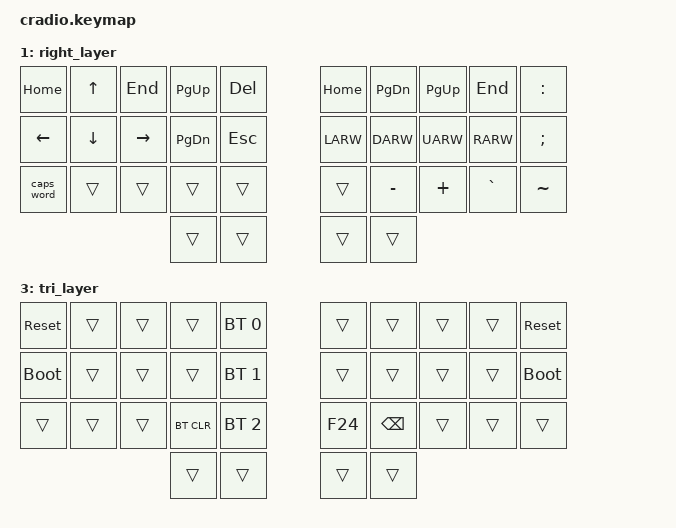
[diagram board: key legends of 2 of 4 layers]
// Copyright (c) 2022 The ZMK Contributors
// SPDX-License-Identifier: MIT

#include <behaviors.dtsi>
#include <dt-bindings/zmk/keys.h>
#include <dt-bindings/zmk/bt.h>

// Home row mods macro
#define HRML(k1,k2,k3,k4) &ht LSHFT k1  &ht LALT k2  &ht LCTRL k3  &ht LGUI k4
#define HRMR(k1,k2,k3,k4) &ht RGUI k1  &ht RCTRL k2  &ht RALT k3  &ht RSHFT k4
#define HYPER(k1) &ht LS(LC(LA(LGUI))) k1
#define HYPER_F(k1) &ht F24 k1
#define MEHL(k1) &ht LS(LC(LA))) k1
#define MEHR(K1) &ht RS(RC(RA))) k1

/ {
    behaviors {
        ht: hold_tap {
            label = "hold_tap";
            compatible = "zmk,behavior-hold-tap";
            #binding-cells = <2>;
            flavor = "tap-preferred";
            tapping-term-ms = <220>;
            quick-tap-ms = <150>;
            global-quick-tap;
            bindings = <&kp>, <&kp>;
        };
    };

    conditional_layers {
        compatible = "zmk,conditional-layers";
        tri_layer {
            if-layers = <1 2>;
            then-layer = <3>;
        };
    };

    keymap {
        compatible = "zmk,keymap";
        default_layer {
            bindings = <
        //╭──────────┬──────────┬──────────┬──────────┬──────────╮   ╭──────────┬──────────┬──────────┬──────────┬──────────╮
        //│  Q       │  W       │  E       │  R       │  T       │   │  Y       │  U       │  I       │  O       │  P       │
            HYPER(Q)    &kp W      &kp E      &kp R      &kp T          &kp Y      &kp U      &kp I      &kp O     HYPER(P)
        //├──────────┼──────────┼──────────┼──────────┼──────────┤   ├──────────┼──────────┼──────────┼──────────┼──────────┤
        //│  A       │  S       │  D       │  F       │  G       │   │  H       │  J       │  K       │  L       │ ' "      │
            HRML(A,        S,         D,         F)     MEHL(G)       MEHR(H)    HRMR(J,        K,         L,        SQT)
        //├──────────┼──────────┼──────────┼──────────┼──────────┤   ├──────────┼──────────┼──────────┼──────────┼──────────┤
        //│  Z       │  X       │  C       │  V       │  B       │   │  N       │  M       │ , <      │ . >      │ / ?      │
            HYPER_F(Z)    &kp X      &kp C      &kp V      &kp B          &kp N      &kp M      &kp COMMA  &kp DOT    HYPER_F(FSLH)
        //╰──────────┴──────────┴──────────┼──────────┼──────────┤   ├──────────┼──────────┼──────────┴──────────┴──────────╯
                                            &lt 2 TAB   &kp SPACE     &kp ENTER  &lt 1 BSPC
        //                                 ╰──────────┴──────────╯   ╰──────────┴──────────╯
            >;
        };

        right_layer {
            bindings = <
        //╭──────────┬──────────┬──────────┬──────────┬──────────╮   ╭──────────┬──────────┬──────────┬──────────┬──────────╮
        //│ HOME     │ UP       │  END     │ PAGE UP  │ DEL      │   │ HOME     │ PAGE DN  │ PAGE UP  │ END      │  :       │
            &kp HOME   &kp UP     &kp END   &kp PG_UP  &kp DEL          &kp HOME   &kp PG_DN  &kp PG_UP  &kp END    &kp COLON
        //├──────────┼──────────┼──────────┼──────────┼──────────┤   ├──────────┼──────────┼──────────┼──────────┼──────────┤
        //│ LEFT     │  DOWN    │ RIHT     │ PAGE DOWN│ ESC      │   │ LEFT     │ DOWN     │ UP       │ RIGHT    │  ;       │
           &kp LEFT   &kp DOWN   &kp RIGHT  &kp PG_DN  &kp ESC         &kp LARW   &kp DARW   &kp UARW   &kp RARW   &kp SEMI
        //├──────────┼──────────┼──────────┼──────────┼──────────┤   ├──────────┼──────────┼──────────┼──────────┼──────────┤
        //│ CAPS     │ PRINT SC │volume up │volume dwn│  Next    │   │ PREV SONG│    -     │     +    │   `      │   ~      │
           &caps_word  &trans   &trans      &trans     &trans         &trans      &kp MINUS  &kp PLUS   &kp GRAVE  &kp TILDE
        //╰──────────┴──────────┴──────────┼──────────┼──────────┤   ├──────────┼──────────┼──────────┴──────────┴──────────╯
                                             &trans      &trans        &trans     &trans
        //                                 ╰──────────┴──────────╯   ╰──────────┴──────────╯
            >;
        };

        left_layer {
            bindings = <
        //╭──────────┬──────────┬──────────┬──────────┬──────────╮   ╭──────────┬──────────┬──────────┬──────────┬──────────╮
        //│    !     │  @       │  #       │  $       │ %        │   │  ^       │  &       │  *       │  (       │  )       │
            &kp EXCL   &kp AT     &kp HASH   &kp DLLR   &kp PRCNT      &kp CARET   &kp AMPS   &kp ASTRK  &kp LPAR  &kp RPAR  
        //├──────────┼──────────┼──────────┼──────────┼──────────┤   ├──────────┼──────────┼──────────┼──────────┼──────────┤
        //│   1      │  2       │  3       │  4       │  5       │   │  6       │  7       │  8       │  9       │  0       │
            HRML(N1,    N2,       N3,        N4)        &kp N5         &kp N6     HRMR(N7,   N8,        N9,         N0)
        //├──────────┼──────────┼──────────┼──────────┼──────────┤   ├──────────┼──────────┼──────────┼──────────┼──────────┤
        //│  esc     │          │  _       │    =     │  del     │   │  [       │   ]      │  <       │  >       │         │
           &kp ESC     &kp BSLH  &kp UNDER &kp EQUAL   &kp DEL       &kp LBKT    &kp RBKT   &kp LT     &kp GT     &kp PIPE  
        //╰──────────┴──────────┴──────────┼──────────┼──────────┤   ├──────────┼──────────┼──────────┴──────────┴──────────╯
                                             &trans     &trans         &trans     &trans
        //                                 ╰──────────┴──────────╯   ╰──────────┴──────────╯
            >;
        };

        tri_layer {
            bindings = <
        //╭──────────┬──────────┬──────────┬──────────┬──────────╮   ╭──────────┬──────────┬──────────┬──────────┬──────────╮
        //│ RESET    │          │          │          │PROFILE 0 │   │          │          │          │          │  RESET   │
            &sys_reset  &trans     &trans     &trans    &bt BT_SEL 0    &trans     &trans     &trans     &trans   &sys_reset
        //├──────────┼──────────┼──────────┼──────────┼──────────┤   ├──────────┼──────────┼──────────┼──────────┼──────────┤
        //│BOOTLOADER│          │          │          │PROFILE 1 │   │          │          │          │          │BOOTLOADER│
          &bootloader  &trans     &trans     &trans    &bt BT_SEL 1    &trans     &trans     &trans     &trans    &bootloader
        //├──────────┼──────────┼──────────┼──────────┼──────────┤   ├──────────┼──────────┼──────────┼──────────┼──────────┤
        //│          │          │          │ CLEAR BT │PROFILE 2 │   │          │          │          │          │          │
            &trans     &trans     &trans    &bt BT_CLR &bt BT_SEL 2    &kp F24     &kp BSPC   &trans     &trans     &trans
        //╰──────────┴──────────┴──────────┼──────────┼──────────┤   ├──────────┼──────────┼──────────┴──────────┴──────────╯
                                             &trans     &trans         &trans     &trans
        //                                 ╰──────────┴──────────╯   ╰──────────┴──────────╯
            >;
        };
    };
};
